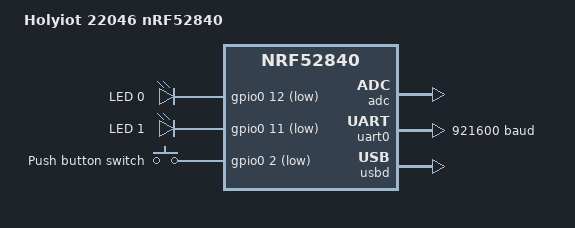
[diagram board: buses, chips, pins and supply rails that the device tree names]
/*
 * Holyiot 22046 nRF52840 devicetree
 * SPDX-License-Identifier: Apache-2.0
 *
 * Assumes nRF52840 QIAA (same as Holyiot-22043). Verify LED/button/uart pinout
 * against your Holyiot 22046 module or breakout board schematic.
 */

/dts-v1/;
#include <nordic/nrf52840_qiaa.dtsi>
#include "holyiot_22046-pinctrl.dtsi"

/ {
	model = "Holyiot 22046 nRF52840";
	compatible = "holyiot,22046";

	chosen {
		zephyr,console = &uart0;
		zephyr,shell-uart = &uart0;
		zephyr,uart-mcumgr = &uart0;
		zephyr,bt-mon-uart = &uart0;
		zephyr,bt-c2h-uart = &uart0;
		zephyr,sram = &sram0;
		zephyr,flash = &flash0;
		zephyr,code-partition = &code_partition;
	};

	leds {
		compatible = "gpio-leds";
		/* LED1 green (schematic 22046-52840 dongle) */
		led0: led_0 {
			gpios = <&gpio0 12 GPIO_ACTIVE_LOW>;
			label = "LED 0";
		};
		/* LED2 Red channel from RGB (schematic 22046-52840 dongle) */
		led1: led_1 {
			gpios = <&gpio0 11 GPIO_ACTIVE_LOW>;
			label = "LED 1";
		};
	};

	buttons {
		compatible = "gpio-keys";
		button0: button_0 {
			gpios = <&gpio0 2 (GPIO_PULL_UP | GPIO_ACTIVE_LOW)>;
			label = "Push button switch";
		};
	};

	aliases {
		led0 = &led0;
		led1 = &led1;
		sw0 = &button0;
	};
};

&adc {
	status = "okay";
};

&gpiote {
	status = "okay";
};

&gpio0 {
	status = "okay";
};

&gpio1 {
	status = "okay";
};

&uart0 {
	compatible = "nordic,nrf-uart";
	current-speed = <921600>;
	status = "okay";
	pinctrl-0 = <&uart0_default>;
	pinctrl-1 = <&uart0_sleep>;
	pinctrl-names = "default", "sleep";
};

&flash0 {
	partitions {
		compatible = "fixed-partitions";
		#address-cells = <1>;
		#size-cells = <1>;

		/* Standalone: app at 0x0 for direct SWD flash (nrfjprog --chiperase).
		   DFU via bootloader requires different layout - use SWD for now. */
		code_partition: partition@0 {
			label = "code_partition";
			reg = <0x00000000 0x000f8000>;
		};

		storage_partition: partition@f8000 {
			label = "storage";
			reg = <0x000f8000 0x00008000>;
		};
	};
};

zephyr_udc0: &usbd {
	compatible = "nordic,nrf-usbd";
	status = "okay";
};
